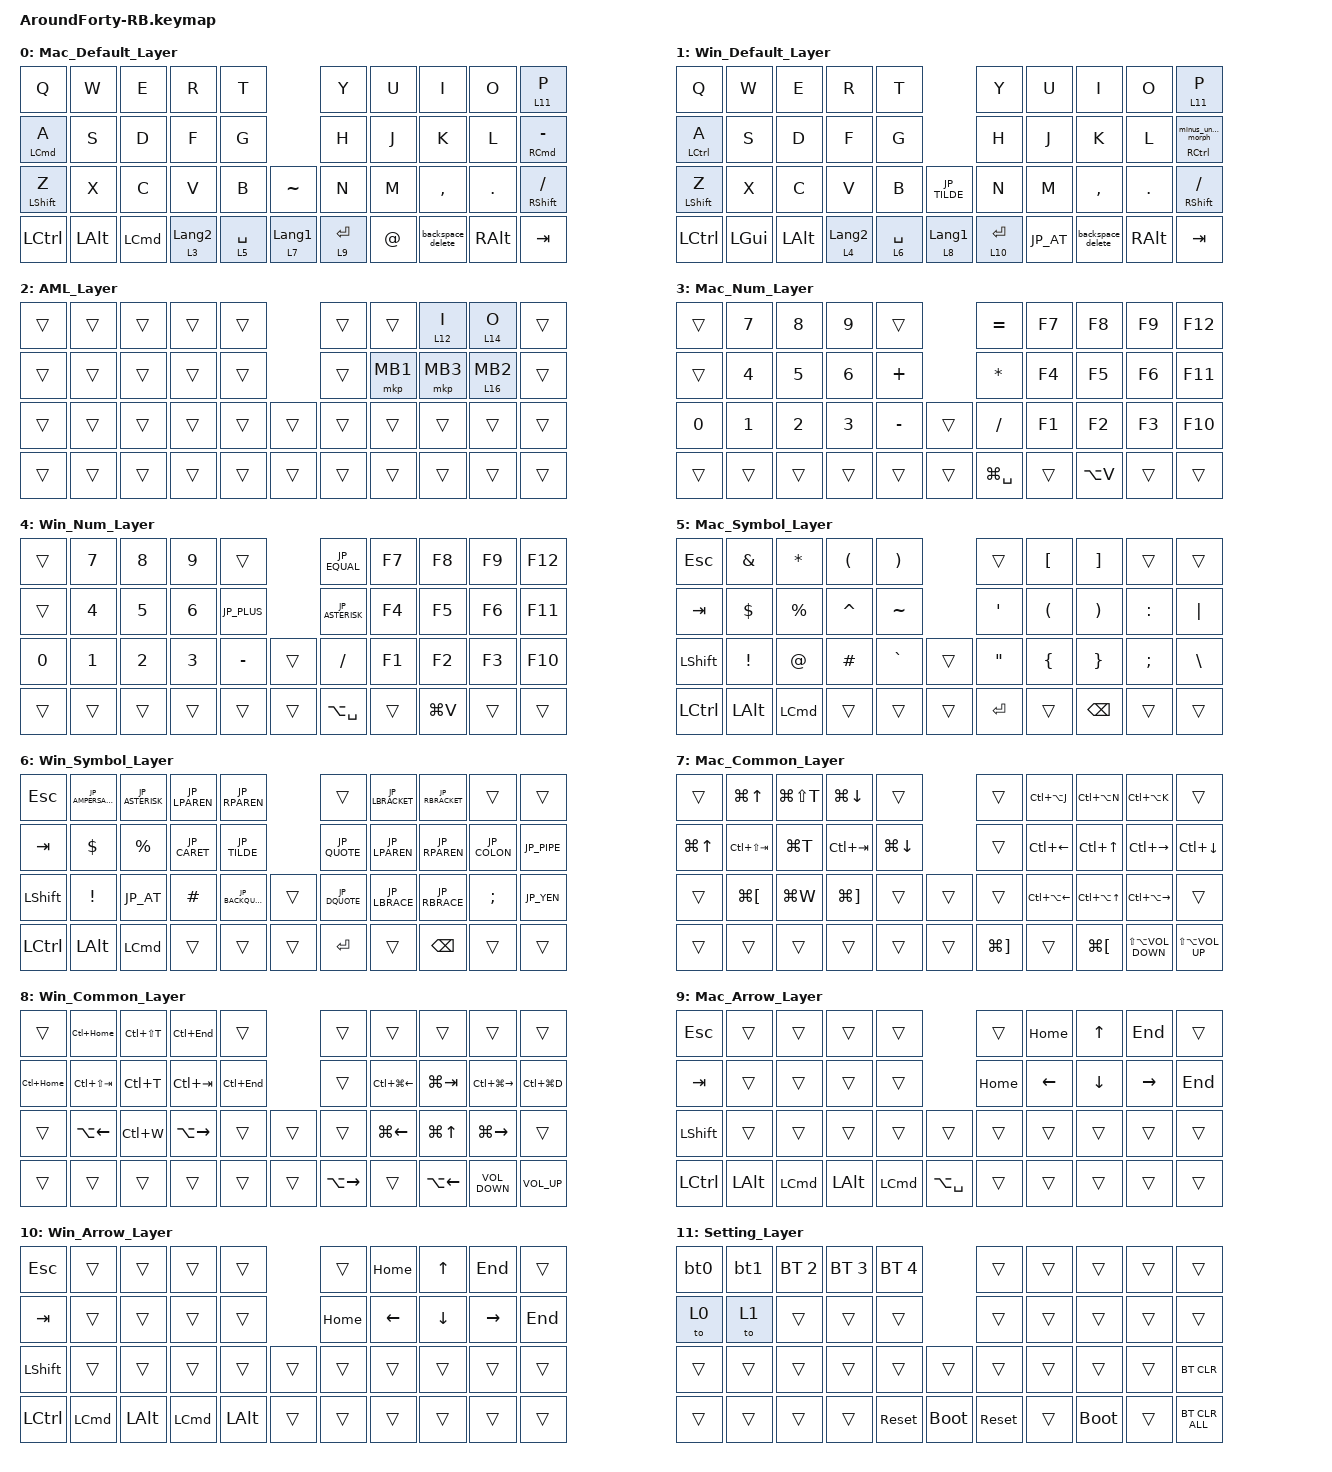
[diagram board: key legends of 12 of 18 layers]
#include <behaviors/rgbled_widget.dtsi>
#include <behaviors.dtsi>
#include <dt-bindings/zmk/bt.h>
#include <dt-bindings/zmk/keys.h>
#include <dt-bindings/zmk/pointing.h>

// OS設定を日本語キーボードのまま使用するための変換定義

#define JP_DQUOTE       AT                // "
#define JP_AMPERSAND    CARET             // &
#define JP_QUOTE        AMPERSAND         // '
#define JP_EQUAL        UNDER             // =
#define JP_CARET        EQUAL             // ^
#define JP_YEN          0x89              // ¥
#define JP_PLUS         COLON             // +
#define JP_TILDE        PLUS              // ~
#define JP_PIPE         LS(0x89)          // |
#define JP_AT           LEFT_BRACKET      // @
#define JP_COLON        SINGLE_QUOTE      // :
#define JP_ASTERISK     DOUBLE_QUOTES     // *
#define JP_BACKQUOTE    LEFT_BRACE        // `
#define JP_UNDERSCORE   LS(0x87)          // _
#define JP_LBRACKET     RIGHT_BRACKET     // [
#define JP_RBRACKET     BACKSLASH         // ]
#define JP_LPAREN       ASTERISK          // (
#define JP_RPAREN       LEFT_PARENTHESIS  // )
#define JP_LBRACE       RIGHT_BRACE       // {
#define JP_RBRACE       PIPE              // }
#define JP_KANA         LANGUAGE_1        // かな
#define JP_EISU         LANGUAGE_2        // 英数
#define JP_HANZEN       GRAVE             // 半角/全角

&mt {
    flavor = "balanced";
    quick-tap-ms = <0>;
};

/ {
    conditional_layers {
        compatible = "zmk,conditional-layers";

        i_gesture_win {
            if-layers = <1 12>;
            then-layer = <13>;
        };

        o_gesture_win {
            if-layers = <1 14>;
            then-layer = <15>;
        };

        l_gesture_win {
            if-layers = <1 16>;
            then-layer = <17>;
        };
    };

    combos {
        compatible = "zmk,combos";

        tab {
            bindings = <&kp TAB>;
            key-positions = <11 12>;
        };

        shift+tab {
            bindings = <&kp LS(TAB)>;
            key-positions = <12 13>;
        };

        escape {
            bindings = <&kp ESCAPE>;
            key-positions = <10 11>;
        };

        scroll {
            bindings = <&mo 7>;
            key-positions = <17 18>;
        };

        mute {
            bindings = <&kp K_MUTE>;
            key-positions = <40 41>;
            layers = <7 8>;
        };
    };

    macros {
        to_layer_0: to_layer_0 {
            compatible = "zmk,behavior-macro-one-param";
            #binding-cells = <1>;
            bindings = <&to 0 &macro_param_1to1 &kp MACRO_PLACEHOLDER>;
            label = "TO_LAYER_0";
        };

        // Windows用入力切り替え：Alt + Grave (~)

        ime_tog: ime_toggle {
            compatible = "zmk,behavior-macro";
            #binding-cells = <0>;
            bindings =
                <&macro_press>,
                <&kp LALT>,
                <&macro_tap>,
                <&kp GRAVE>,
                <&macro_release>,
                <&kp LALT>;
        };

        // macOS用入力切り替え：Ctrl + Space

        mac_ime: mac_ime_toggle {
            compatible = "zmk,behavior-macro";
            #binding-cells = <0>;
            bindings =
                <&macro_press>,
                <&kp LCTRL>,
                <&macro_tap>,
                <&kp SPACE>,
                <&macro_release>,
                <&kp LCTRL>;
        };

        bt0: bt0 {
            compatible = "zmk,behavior-macro";
            #binding-cells = <0>;
            bindings = <&bt BT_SEL 0>, <&macro_wait_time 500>, <&to 0>;

            label = "BT0";
        };

        bt1: bt1 {
            compatible = "zmk,behavior-macro";
            #binding-cells = <0>;
            bindings = <&bt BT_SEL 1>, <&macro_wait_time 500>, <&to 1>;

            label = "BT1";
        };

        exit_AML: exit_AML {
            compatible = "zmk,behavior-macro";
            wait-ms = <0>;
            tap-ms = <0>;
            #binding-cells = <0>;
            bindings = <&tog_off 2>;
            label = "exit_AML";
        };

        kp_exit_AML: kp_exit_AML {
            compatible = "zmk,behavior-macro-one-param";
            wait-ms = <0>;
            tap-ms = <0>;
            #binding-cells = <1>;
            bindings = <&macro_param_1to1 &kp MACRO_PLACEHOLDER &exit_AML>;
            label = "KP_exit_AML";
        };

    };

    behaviors {
        lt_to_layer_0: lt_to_layer_0 {
            compatible = "zmk,behavior-hold-tap";
            label = "LAYER_TAP_TO_0";
            bindings = <&mo>, <&to_layer_0>;

            #binding-cells = <2>;
            tapping-term-ms = <200>;
        };

        // 

        scroll_up_down: behavior_sensor_rotate_mouse_wheel_up_down {
            compatible = "zmk,behavior-sensor-rotate";
            #sensor-binding-cells = <0>;
            bindings = <&msc SCRL_UP>, <&msc SCRL_DOWN>;

            tap-ms = <20>;
        };

        minus_under_morph: minus_under_morph {
            compatible = "zmk,behavior-mod-morph";
            #binding-cells = <0>;
            bindings = <&kp MINUS>, <&kp JP_UNDERSCORE>;

            mods = <(MOD_LSFT|MOD_RSFT)>;
        };

        // 長押しで指定したキー, タップで "-", Shift+タップで "_"

        minus_under: minus_under {
            compatible = "zmk,behavior-hold-tap";
            bindings = <&kp>, <&minus_under_morph>;

            #binding-cells = <2>;
            flavor = "balanced";
            tapping-term-ms = <200>;
            quick-tap-ms = <200>;
        };

        backspace_delete: backspace_delete {
            compatible = "zmk,behavior-mod-morph";
            label = "BACKSPACE_DELETE";
            bindings = <&kp BACKSPACE>, <&kp DELETE>;

            #binding-cells = <0>;
            mods = <(MOD_LSFT|MOD_RSFT)>;
        };

        tog_off: toggle_layer_off {
            compatible = "zmk,behavior-toggle-layer";
            #binding-cells = <1>;
            display-name = "Toggle Layer Off";
            toggle-mode = "off";
        };

        mt_exit_AML_on_tap: mt_exit_AML_on_tap {
            compatible = "zmk,behavior-hold-tap";
            label = "MT_exit_AML_ON_TAP";
            bindings = <&kp>, <&kp_exit_AML>;

            #binding-cells = <2>;
            tapping-term-ms = <200>;
            flavor = "balanced";
            quick-tap-ms = <200>;
        };

        gesture_layer_kp: gesture_layer_kp {
            compatible = "zmk,behavior-hold-tap";
            label = "GESTURE_LAYER_KEY_TAP";
            bindings = <&mo>, <&kp>;

            #binding-cells = <2>;
            tapping-term-ms = <200>;
            flavor = "hold-preferred";
            hold-while-undecided;
        };

        gesture_layer_mkp: gesture_layer_mkp {
            compatible = "zmk,behavior-hold-tap";
            label = "GESTURE_LAYER_MOUSE_TAP";
            bindings = <&mo>, <&mkp>;

            #binding-cells = <2>;
            tapping-term-ms = <200>;
            flavor = "hold-preferred";
            hold-while-undecided;
        };
    };

    keymap {
        compatible = "zmk,keymap";

        Mac_Default_Layer {
            bindings = <
&kp Q                               &kp W         &kp E             &kp R             &kp T                          &kp Y        &kp U        &kp I              &kp O          &lt 11 P
&mt_exit_AML_on_tap LEFT_COMMAND A  &kp S         &kp D             &kp F             &kp G                          &kp H        &kp J        &kp K              &kp L          &mt_exit_AML_on_tap RIGHT_COMMAND MINUS
&mt_exit_AML_on_tap LEFT_SHIFT Z    &kp X         &kp C             &kp V             &kp B        &kp TILDE         &kp N        &kp M        &kp COMMA          &kp PERIOD     &mt_exit_AML_on_tap RIGHT_SHIFT SLASH
&kp LCTRL                           &kp LEFT_ALT  &kp LEFT_COMMAND  &lt 3 LANGUAGE_2  &lt 5 SPACE  &lt 7 LANGUAGE_1  &lt 9 ENTER  &kp AT_SIGN  &backspace_delete  &kp RIGHT_ALT  &kp TAB
            >;
        };

        Win_Default_Layer {
            bindings = <
&kp Q               &kp W         &kp E         &kp R             &kp T                          &kp Y         &kp U      &kp I              &kp O          &lt 11 P
&mt LEFT_CONTROL A  &kp S         &kp D         &kp F             &kp G                          &kp H         &kp J      &kp K              &kp L          &minus_under RIGHT_CONTROL 0
&mt LEFT_SHIFT Z    &kp X         &kp C         &kp V             &kp B        &kp JP_TILDE      &kp N         &kp M      &kp COMMA          &kp PERIOD     &mt_exit_AML_on_tap RIGHT_SHIFT SLASH
&kp LCTRL           &kp LEFT_GUI  &kp LEFT_ALT  &lt 4 LANGUAGE_2  &lt 6 SPACE  &lt 8 LANGUAGE_1  &lt 10 ENTER  &kp JP_AT  &backspace_delete  &kp RIGHT_ALT  &kp TAB
            >;
        };

        AML_Layer {
            bindings = <
&trans  &trans  &trans  &trans  &trans          &trans  &trans    &gesture_layer_kp 12 I  &gesture_layer_kp 14 O  &trans
&trans  &trans  &trans  &trans  &trans          &trans  &mkp MB1  &mkp MB3                 &gesture_layer_mkp 16 MB2  &trans
&trans  &trans  &trans  &trans  &trans  &trans  &trans  &trans    &trans    &trans    &trans
&trans  &trans  &trans  &trans  &trans  &trans  &trans  &trans    &trans    &trans    &trans
            >;
        };

        Mac_Num_Layer {
            bindings = <
&trans        &kp NUMBER_7  &kp NUMBER_8  &kp NUMBER_9  &trans             &kp EQUAL      &kp F7  &kp F8     &kp F9  &kp F12
&trans        &kp NUMBER_4  &kp NUMBER_5  &kp NUMBER_6  &kp PLUS           &kp ASTERISK   &kp F4  &kp F5     &kp F6  &kp F11
&kp NUMBER_0  &kp NUMBER_1  &kp NUMBER_2  &kp NUMBER_3  &kp MINUS  &trans  &kp SLASH      &kp F1  &kp F2     &kp F3  &kp F10
&trans        &trans        &trans        &trans        &trans     &trans  &kp LG(SPACE)  &trans  &kp LA(V)  &trans  &trans
            >;
        };

        Win_Num_Layer {
            bindings = <
&trans        &kp NUMBER_7  &kp NUMBER_8  &kp NUMBER_9  &trans               &kp JP_EQUAL     &kp F7  &kp F8     &kp F9  &kp F12
&trans        &kp NUMBER_4  &kp NUMBER_5  &kp NUMBER_6  &kp JP_PLUS          &kp JP_ASTERISK  &kp F4  &kp F5     &kp F6  &kp F11
&kp NUMBER_0  &kp NUMBER_1  &kp NUMBER_2  &kp NUMBER_3  &kp MINUS    &trans  &kp SLASH        &kp F1  &kp F2     &kp F3  &kp F10
&trans        &trans        &trans        &trans        &trans       &trans  &kp LA(SPACE)    &trans  &kp LG(V)  &trans  &trans
            >;
        };

        Mac_Symbol_Layer {
            bindings = <
&kp ESCAPE        &kp AMPERSAND    &kp ASTERISK      &kp LEFT_PARENTHESIS  &kp RIGHT_PARENTHESIS          &trans             &kp LEFT_BRACKET      &kp RIGHT_BRACKET      &trans         &trans
&kp TAB           &kp DOLLAR       &kp PERCENT       &kp CARET             &kp TILDE                      &kp SINGLE_QUOTE   &kp LEFT_PARENTHESIS  &kp RIGHT_PARENTHESIS  &kp COLON      &kp PIPE
&kp LEFT_SHIFT    &kp EXCLAMATION  &kp AT_SIGN       &kp HASH              &kp GRAVE              &trans  &kp DOUBLE_QUOTES  &kp LEFT_BRACE        &kp RIGHT_BRACE        &kp SEMICOLON  &kp BACKSLASH
&kp LEFT_CONTROL  &kp LEFT_ALT     &kp LEFT_COMMAND  &trans                &trans                 &trans  &kp ENTER          &trans                &kp BACKSPACE          &trans         &trans
            >;
        };

        Win_Symbol_Layer {
            bindings = <
&kp ESCAPE        &kp JP_AMPERSAND  &kp JP_ASTERISK   &kp JP_LPAREN  &kp JP_RPAREN             &trans         &kp JP_LBRACKET  &kp JP_RBRACKET  &trans         &trans
&kp TAB           &kp DOLLAR        &kp PERCENT       &kp JP_CARET   &kp JP_TILDE              &kp JP_QUOTE   &kp JP_LPAREN    &kp JP_RPAREN    &kp JP_COLON   &kp JP_PIPE
&kp LEFT_SHIFT    &kp EXCLAMATION   &kp JP_AT         &kp HASH       &kp JP_BACKQUOTE  &trans  &kp JP_DQUOTE  &kp JP_LBRACE    &kp JP_RBRACE    &kp SEMICOLON  &kp JP_YEN
&kp LEFT_CONTROL  &kp LEFT_ALT      &kp LEFT_COMMAND  &trans         &trans            &trans  &kp ENTER      &trans           &kp BACKSPACE    &trans         &trans
            >;
        };

        Mac_Common_Layer {
            bindings = <
&trans            &kp LG(UP_ARROW)      &kp LG(LS(T))  &kp LG(DOWN_ARROW)     &trans                      &trans                 &kp LC(LA(J))           &kp LC(LA(N))         &kp LC(LA(K))              &trans
&kp LG(UP_ARROW)  &kp LC(LS(TAB))       &kp LG(T)      &kp LC(TAB)            &kp LG(DOWN_ARROW)          &trans                 &kp LC(LEFT_ARROW)      &kp LC(UP_ARROW)      &kp LC(RIGHT_ARROW)        &kp LC(DOWN_ARROW)
&trans            &kp LG(LEFT_BRACKET)  &kp LG(W)      &kp LG(RIGHT_BRACKET)  &trans              &trans  &trans                 &kp LC(LA(LEFT_ARROW))  &kp LC(LA(UP_ARROW))  &kp LC(LA(RIGHT_ARROW))    &trans
&trans            &trans                &trans         &trans                 &trans              &trans  &kp LG(RIGHT_BRACKET)  &trans                  &kp LG(LEFT_BRACKET)  &kp LS(LA(C_VOLUME_DOWN))  &kp LS(LA(C_VOLUME_UP))
            >;
        };

        Win_Common_Layer {
            bindings = <
&trans        &kp LC(HOME)        &kp LC(LS(T))  &kp LC(END)          &trans               &trans               &trans                  &trans              &trans                   &trans
&kp LC(HOME)  &kp LC(LS(TAB))     &kp LC(T)      &kp LC(TAB)          &kp LC(END)          &trans               &kp LC(LG(LEFT_ARROW))  &kp LG(TAB)         &kp LC(LG(RIGHT_ARROW))  &kp LC(LG(D))
&trans        &kp LA(LEFT_ARROW)  &kp LC(W)      &kp LA(RIGHT_ARROW)  &trans       &trans  &trans               &kp LG(LEFT_ARROW)      &kp LG(UP_ARROW)    &kp LG(RIGHT_ARROW)      &trans
&trans        &trans              &trans         &trans               &trans       &trans  &kp LA(RIGHT_ARROW)  &trans                  &kp LA(LEFT_ARROW)  &kp C_VOLUME_DOWN        &kp C_VOLUME_UP
            >;
        };

        Mac_Arrow_Layer {
            bindings = <
&kp ESCAPE      &trans        &trans            &trans        &trans                           &trans    &kp HOME        &kp UP_ARROW    &kp END          &trans
&kp TAB         &trans        &trans            &trans        &trans                           &kp HOME  &kp LEFT_ARROW  &kp DOWN_ARROW  &kp RIGHT_ARROW  &kp END
&kp LEFT_SHIFT  &trans        &trans            &trans        &trans            &trans         &trans    &trans          &trans          &trans           &trans
&kp LCTRL       &kp LEFT_ALT  &kp LEFT_COMMAND  &kp LEFT_ALT  &kp LEFT_COMMAND  &kp LA(SPACE)  &trans    &trans          &trans          &trans           &trans
            >;
        };

        Win_Arrow_Layer {
            bindings = <
&kp ESCAPE      &trans            &trans        &trans            &trans                &trans    &kp HOME        &kp UP_ARROW    &kp END          &trans
&kp TAB         &trans            &trans        &trans            &trans                &kp HOME  &kp LEFT_ARROW  &kp DOWN_ARROW  &kp RIGHT_ARROW  &kp END
&kp LEFT_SHIFT  &trans            &trans        &trans            &trans        &trans  &trans    &trans          &trans          &trans           &trans
&kp LCTRL       &kp LEFT_COMMAND  &kp LEFT_ALT  &kp LEFT_COMMAND  &kp LEFT_ALT  &trans  &trans    &trans          &trans          &trans           &trans
            >;
        };

        Setting_Layer {
            bindings = <
&bt0    &bt1    &bt BT_SEL 2  &bt BT_SEL 3  &bt BT_SEL 4               &trans      &trans  &trans       &trans  &trans
&to 0   &to 1   &trans        &trans        &trans                     &trans      &trans  &trans       &trans  &trans
&trans  &trans  &trans        &trans        &trans        &trans       &trans      &trans  &trans       &trans  &bt BT_CLR
&trans  &trans  &trans        &trans        &sys_reset    &bootloader  &sys_reset  &trans  &bootloader  &trans  &bt BT_CLR_ALL
            >;
        };

        I_Gesture_Layer {
            bindings = <
&trans  &trans  &trans  &trans  &trans          &trans  &trans  &trans  &kp LC(UP_ARROW)  &trans
&trans  &trans  &trans  &trans  &trans          &trans  &trans  &trans  &trans  &trans
&trans  &trans  &trans  &trans  &trans  &trans  &trans  &trans  &trans  &trans  &trans
&trans  &trans  &trans  &trans  &trans  &trans  &trans  &trans  &trans  &trans  &trans
            >;
        };

        I_Gesture_Win_Layer {
            bindings = <
&trans  &trans  &trans  &trans  &trans          &trans  &trans  &trans  &kp LG(TAB)  &trans
&trans  &trans  &trans  &trans  &trans          &trans  &trans  &trans  &trans  &trans
&trans  &trans  &trans  &trans  &trans  &trans  &trans  &trans  &trans  &trans  &trans
&trans  &trans  &trans  &trans  &trans  &trans  &trans  &trans  &trans  &trans  &trans
            >;
        };

        O_Gesture_Layer {
            bindings = <
&trans  &trans  &trans  &trans  &trans          &trans  &trans  &kp LC(UP_ARROW)  &trans  &trans
&trans  &trans  &trans  &trans  &trans          &trans  &trans  &trans  &trans  &trans
&trans  &trans  &trans  &trans  &trans  &trans  &trans  &trans  &trans  &trans  &trans
&trans  &trans  &trans  &trans  &trans  &trans  &trans  &trans  &trans  &trans  &trans
            >;
        };

        O_Gesture_Win_Layer {
            bindings = <
&trans  &trans  &trans  &trans  &trans          &trans  &trans  &kp LG(TAB)  &trans  &trans
&trans  &trans  &trans  &trans  &trans          &trans  &trans  &trans  &trans  &trans
&trans  &trans  &trans  &trans  &trans  &trans  &trans  &trans  &trans  &trans  &trans
&trans  &trans  &trans  &trans  &trans  &trans  &trans  &trans  &trans  &trans  &trans
            >;
        };

        L_Gesture_Layer {
            bindings = <
&trans  &trans  &trans  &trans  &trans          &trans  &trans  &trans  &trans  &trans
&trans  &trans  &trans  &trans  &trans          &trans  &trans  &trans  &trans  &trans
&trans  &trans  &trans  &trans  &trans  &trans  &trans  &trans  &trans  &trans  &trans
&trans  &trans  &trans  &trans  &trans  &trans  &trans  &trans  &trans  &trans  &trans
            >;
        };

        L_Gesture_Win_Layer {
            bindings = <
&trans  &trans  &trans  &trans  &trans          &trans  &trans  &trans  &trans  &trans
&trans  &trans  &trans  &trans  &trans          &trans  &trans  &trans  &trans  &trans
&trans  &trans  &trans  &trans  &trans  &trans  &trans  &trans  &trans  &trans  &trans
&trans  &trans  &trans  &trans  &trans  &trans  &trans  &trans  &trans  &trans  &trans
            >;
        };
    };
};
